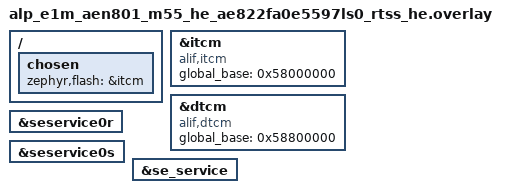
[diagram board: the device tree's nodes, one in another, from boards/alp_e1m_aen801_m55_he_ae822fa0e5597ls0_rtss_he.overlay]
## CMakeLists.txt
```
# SPDX-License-Identifier: Apache-2.0
#
# aen-se-crypto -- drive the portable <alp/security.h> compute surface
# (SHA-256 known-answer + AES-128-GCM round-trip + TRNG) on the E1M-AEN801
# (Ensemble E8, M55-HE) backed by the Secure Enclave's CryptoCell.  The
# companion to aen-se-service-query (which proves the READ-ONLY SE surface);
# this app exercises the *compute* services that ride the same MHUv2 -> SE
# mailbox, through the SE-CryptoCell security backend
# (src/backends/security/se_cryptocell.c).
#
# Plain prj.conf app (no alp_project.py board.yaml emit): the SE-service
# stack Kconfigs (CONFIG_ARM_MHUV2 / CONFIG_HAS_ALIF_SE_SERVICES) and the
# SE-CryptoCell backend gate (CONFIG_ALP_SDK_SECURITY_SE_CRYPTOCELL) are
# sourced under CONFIG_ALP_SDK, which prj.conf sets; the overlay okays the
# MHUv2 nodes + the se_service root node and supplies the itcm/dtcm
# global_base the SE address translation needs.

cmake_minimum_required(VERSION 3.20)

# No DTC_OVERLAY_FILE: Zephyr applies boards/<fully-qualified-board>.overlay
# by itself, so the AEN801 and AEN803 targets each read their own file.

find_package(Zephyr REQUIRED HINTS $ENV{ZEPHYR_BASE})
project(aen_se_crypto LANGUAGES C)

target_sources(app PRIVATE src/main.c)
```

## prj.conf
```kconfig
# SPDX-License-Identifier: Apache-2.0
#
# Bench RAM-run config for the E1M-AEN801 (M55-HE).

# Tier-2 driver Kconfigs (incl. CONFIG_ARM_MHUV2 / CONFIG_HAS_ALIF_SE_SERVICES
# and the alp-sdk security backends) are gated under ALP_SDK.
CONFIG_ALP_SDK=y

# SE service transport.  CONFIG_ARM_MHUV2 builds the in-tree "arm,mhuv2" IPM
# driver (zephyr/drivers/ipm/ipm_arm_mhuv2.c) and pulls in CONFIG_IPM;
# CONFIG_HAS_ALIF_SE_SERVICES compiles the hal_alif SE client
# (se_services/zephyr/src/se_service.c) the SE-CryptoCell backend rides.
CONFIG_ARM_MHUV2=y
CONFIG_HAS_ALIF_SE_SERVICES=y

# SE-CryptoCell hardware-crypto backend for <alp/security.h>.  Registers at
# silicon_ref="alif:ensemble:e8" priority 110 (ahead of the "*" PSA backend).
# RNG/TRNG runs live through the public se_service_get_rnd_num(); SHA/AES-GCM
# need the generic send seam below.
CONFIG_ALP_SDK_SECURITY_SE_CRYPTOCELL=y

# The generic SE send-request transport seam DEFAULTS ON (Kconfig default y):
# the public send-request entry now exists (hal_alif patch 0002 exposes
# se_service_send_request), so by default the SE backend's SHA/AES-GCM ops
# compute on-silicon in the SE CryptoCell (bench-validated, Flow C RAM-run) --
# the SE backend binds at priority 110 ahead of PSA.  No override is needed here.
# The MbedTLS-PSA backend below is only the fall-through for algs the SE declines
# (SHA-384/512, over-ceiling single-shot inputs).  To force a PSA-only
# fall-through demo instead, uncomment the next line:
# CONFIG_ALP_SDK_SECURITY_SE_CRYPTOCELL_SEND_SEAM is not set

# MbedTLS-PSA backend, kept as the fall-through for SE-declined algs (the SE
# send seam is ON by default, so SHA-256/AES-GCM run in the SE CryptoCell) --
# proves the portable API contract end to end.  PSA picks the E8 crypto HW
# where MbedTLS's driver layer registers it.
CONFIG_MBEDTLS=y
CONFIG_MBEDTLS_PSA_CRYPTO_C=y
CONFIG_ALP_SDK_SECURITY=y

# PSA wants for the example's ops: SHA-256 (works) + AES-GCM AEAD (the GCM
# round-trip reported "no backend" because PSA AEAD/GCM + AES key type were
# not selected, so the alp PSA backend declined the open).
CONFIG_PSA_WANT_ALG_SHA_256=y
CONFIG_PSA_WANT_ALG_GCM=y
CONFIG_PSA_WANT_KEY_TYPE_AES=y

# MbedTLS-PSA software AES-GCM/SHA is stack- and heap-heavy; the default main
# stack overflows (bench USAGE FAULT: stack overflow). Give the main thread
# room and a PSA heap pool.
CONFIG_MAIN_STACK_SIZE=16384
CONFIG_HEAP_MEM_POOL_SIZE=16384

# Console: Alp UART console -- E1M edge UART0 (Alif UART5, P3_4/P3_5, 115200
# 8N1, NS16550), the E1M-AEN801 carrier console. The board _defconfig already
# selects it; we set it explicitly here so the example is self-describing.
CONFIG_SERIAL=y
CONFIG_CONSOLE=y
CONFIG_UART_CONSOLE=y
CONFIG_UART_INTERRUPT_DRIVEN=y
# Serial-less bench? Comment the four lines above and uncomment these to read
# 'ram_console_buf' over SWD instead:
# CONFIG_RAM_CONSOLE=y
# CONFIG_RAM_CONSOLE_BUFFER_SIZE=2048
# CONFIG_UART_CONSOLE=n
CONFIG_PRINTK=y

# Keep the image small + deterministic for a RAM-run.
CONFIG_LOG=n
```

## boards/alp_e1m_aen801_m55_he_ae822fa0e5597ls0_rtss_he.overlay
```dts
/*
 * Copyright (c) 2026 Alp Lab AB
 * SPDX-License-Identifier: Apache-2.0
 *
 * aen-se-crypto overlay for the E1M-AEN801 (Ensemble E8, M55-HE) RAM-run.
 *
 * The SE SERVICE transport nodes live in the E8 SoC overlay
 * (zephyr/dts/alif/ensemble_e8_peripherals.dtsi) status="disabled" by
 * default (they are SoC-fixed: the RTSS-HE <-> SE MHUv2 mailbox pair + the
 * se_service root node).  This overlay enables them for the RTSS-HE core:
 *   - seservice0r (arm,mhuv2 @ 0x40040000, IRQ 37, "rx") -- SE -> RTSS in
 *   - seservice0s (arm,mhuv2 @ 0x40050000, IRQ 38, "tx") -- RTSS -> SE out
 *   - se_service  (alif,secure-enclave-services) -- ties the two via phandles
 *
 * Identical SE transport DT to aen-se-service-query; the SE-CryptoCell
 * security backend rides the very same se_service client.
 *
 * No clocks / pinctrl: the MHUv2 mailboxes are core-internal (no pads, no
 * peripheral clock gate); the driver only maps MMIO + wires the IRQ.
 */

/*
 * RAM-run: retarget ROM to ITCM (path-reference form &itcm; the
 * phandle-array form makes FLASH_SIZE=0 and overflows the link) -- the
 * aen-se-service-query precedent.
 */
/ {
	chosen {
		zephyr,flash = &itcm;
		/delete-property/ zephyr,code-partition;
	};
};

/*
 * itcm/dtcm `global_base` for local_to_global() -- the SE-CryptoCell
 * backend (and hal_alif se_service.c) put the outbound SE message buffer
 * through local_to_global() (soc_memory_map.h), which reads
 * DT_PROP(itcm/dtcm, global_base) to translate the M55-local address into
 * the global view the SE's DMA sees, AND the backend translates every
 * embedded send_*_addr the SE dereferences the same way.  Upstream Zephyr's
 * arm,itcm/arm,dtcm bindings have no such prop, so re-`compatible` the nodes
 * onto the alp-sdk alif,itcm/alif,dtcm bindings (which declare global_base)
 * and set the E8 RTSS-HE global TCM aliases (ITCM 0x58000000,
 * DTCM 0x58800000), transcribed from the Apache-2.0 zephyr_alif fork
 * ensemble_rtss_he.dtsi -- the same values the NPU + camera + eth + se-query
 * local_to_global paths use.
 */
&itcm {
	compatible = "alif,itcm";
	global_base = <0x58000000>;
};

&dtcm {
	compatible = "alif,dtcm";
	global_base = <0x58800000>;
};

&seservice0r {
	status = "okay";
};

&seservice0s {
	status = "okay";
};

&se_service {
	status = "okay";
};
```

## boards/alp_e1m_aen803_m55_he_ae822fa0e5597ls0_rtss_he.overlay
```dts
/*
 * Copyright (c) 2026 Alp Lab AB
 * SPDX-License-Identifier: Apache-2.0
 *
 * aen-se-crypto overlay for the E1M-AEN803 (Ensemble E8, M55-HE) RAM-run.
 *
 * The SE SERVICE transport nodes live in the E8 SoC overlay
 * (zephyr/dts/alif/ensemble_e8_peripherals.dtsi) status="disabled" by
 * default (they are SoC-fixed: the RTSS-HE <-> SE MHUv2 mailbox pair + the
 * se_service root node).  This overlay enables them for the RTSS-HE core:
 *   - seservice0r (arm,mhuv2 @ 0x40040000, IRQ 37, "rx") -- SE -> RTSS in
 *   - seservice0s (arm,mhuv2 @ 0x40050000, IRQ 38, "tx") -- RTSS -> SE out
 *   - se_service  (alif,secure-enclave-services) -- ties the two via phandles
 *
 * Identical SE transport DT to aen-se-service-query; the SE-CryptoCell
 * security backend rides the very same se_service client.
 *
 * No clocks / pinctrl: the MHUv2 mailboxes are core-internal (no pads, no
 * peripheral clock gate); the driver only maps MMIO + wires the IRQ.
 */

/*
 * RAM-run: retarget ROM to ITCM (path-reference form &itcm; the
 * phandle-array form makes FLASH_SIZE=0 and overflows the link) -- the
 * aen-se-service-query precedent.
 */
/ {
	chosen {
		zephyr,flash = &itcm;
		/delete-property/ zephyr,code-partition;
	};
};

/*
 * itcm/dtcm `global_base` for local_to_global() -- the SE-CryptoCell
 * backend (and hal_alif se_service.c) put the outbound SE message buffer
 * through local_to_global() (soc_memory_map.h), which reads
 * DT_PROP(itcm/dtcm, global_base) to translate the M55-local address into
 * the global view the SE's DMA sees, AND the backend translates every
 * embedded send_*_addr the SE dereferences the same way.  Upstream Zephyr's
 * arm,itcm/arm,dtcm bindings have no such prop, so re-`compatible` the nodes
 * onto the alp-sdk alif,itcm/alif,dtcm bindings (which declare global_base)
 * and set the E8 RTSS-HE global TCM aliases (ITCM 0x58000000,
 * DTCM 0x58800000), transcribed from the Apache-2.0 zephyr_alif fork
 * ensemble_rtss_he.dtsi -- the same values the NPU + camera + eth + se-query
 * local_to_global paths use.
 */
&itcm {
	compatible = "alif,itcm";
	global_base = <0x58000000>;
};

&dtcm {
	compatible = "alif,dtcm";
	global_base = <0x58800000>;
};

&seservice0r {
	status = "okay";
};

&seservice0s {
	status = "okay";
};

&se_service {
	status = "okay";
};
```

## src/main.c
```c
/*
 * Copyright (c) 2026 Alp Lab AB
 * SPDX-License-Identifier: Apache-2.0
 *
 * aen-se-crypto -- exercise the portable <alp/security.h> surface on the
 * E1M-AEN801 (Ensemble E8, M55-HE) when it is backed by the Secure
 * Enclave's CryptoCell HARDWARE crypto.
 *
 * This is the companion to aen-se-service-query: that app proves the
 * READ-ONLY SE transport binds and answers (heartbeat + LCS + 8-byte TRNG);
 * THIS app drives the *compute* surface that rides the same MHUv2 -> SE
 * mailbox -- a known-answer SHA-256, an AES-128-GCM encrypt/decrypt
 * round-trip, and a true-random pull -- all through the vendor-clean
 * alp_hash_* / alp_aead_* / alp_random_bytes API.  Nothing here names the
 * SE: the SE-CryptoCell backend (src/backends/security/se_cryptocell.c)
 * registers at silicon_ref="alif:ensemble:e8" priority 110 and wins
 * selection over the portable MbedTLS-PSA backend on this part, so the work
 * lands on dedicated silicon transparently.
 *
 * WHAT RUNS WHERE (current bench reality):
 *   - alp_random_bytes  -> SE TRNG, LIVE today (public
 *                          se_service_get_rnd_num under the hood).
 *   - alp_hash_* / alp_aead_*  -> SE CryptoCell SHA / AES-GCM.  These ride the
 *                          generic SE send-request seam
 *                          (CONFIG_ALP_SDK_SECURITY_SE_CRYPTOCELL_SEND_SEAM),
 *                          which DEFAULTS ON, so by default the SE CryptoCell
 *                          computes them on-silicon (bench-validated).  For an
 *                          alg the SE declines (SHA-384/512, over-ceiling
 *                          input) the dispatcher falls through to the
 *                          MbedTLS-PSA backend on the M55.  Either way the API
 *                          contract holds and the RESULT line reports which
 *                          surfaces answered.
 *
 * PASS gate: SHA-256("abc") matches the NIST known-answer vector, the
 * AES-128-GCM ciphertext decrypts back to the plaintext with a valid tag,
 * and the TRNG fill returns ALP_OK with not-all-zero bytes.
 *
 * Bench flow: RAM-run + RAM-console (the app UART is not on USB on this
 * bench; read 'ram_console_buf' over SWD).  Every alp_* call bounds its
 * wait inside the backend, so the app never hangs.
 */

#include <stdbool.h>
#include <stdint.h>
#include <string.h>

#include <zephyr/drivers/entropy.h>
#include <zephyr/kernel.h>
#include <zephyr/random/random.h>
#include <zephyr/sys/printk.h>

#include <alp/security.h>

/*
 * NIST FIPS 180-4 known-answer vector: SHA-256("abc").
 *   ba7816bf 8f01cfea 414140de 5dae2223
 *   b00361a3 96177a9c b410ff61 f20015ad
 */
static const uint8_t k_sha256_abc[32] = {
	0xba, 0x78, 0x16, 0xbf, 0x8f, 0x01, 0xcf, 0xea, 0x41, 0x41, 0x40, 0xde, 0x5d, 0xae, 0x22, 0x23,
	0xb0, 0x03, 0x61, 0xa3, 0x96, 0x17, 0x7a, 0x9c, 0xb4, 0x10, 0xff, 0x61, 0xf2, 0x00, 0x15, 0xad,
};

static void hexdump(const char *label, const uint8_t *p, size_t n)
{
	printk("        %s = ", label);
	for (size_t i = 0u; i < n; i++) {
		printk("%02x", p[i]);
	}
	printk("\n");
}

/* SHA-256("abc") through the portable hash surface. */
static bool test_sha256_abc(void)
{
	alp_hash_t *h = alp_hash_open(ALP_HASH_SHA256);
	if (h == NULL) {
		printk("sha256               : open FAILED (no backend)\n");
		return false;
	}

	uint8_t      digest[32] = { 0 };
	size_t       dlen       = 0u;
	alp_status_t s          = alp_hash_update(h, (const uint8_t *)"abc", 3u);
	if (s == ALP_OK) {
		s = alp_hash_finish(h, digest, sizeof(digest), &dlen);
		/* Contract nuance (<alp/security.h>): finish implicitly closes
		 * the context ON SUCCESS ONLY.  A failed finish leaves the
		 * handle open, so it must be closed explicitly or the backend
		 * slot leaks and later opens start failing. */
		if (s != ALP_OK) {
			alp_hash_close(h);
		}
	} else {
		/* Update failed before finish ever ran: release the handle
		 * (close is the "abandon without finalising" path). */
		alp_hash_close(h);
	}

	const bool ok = (s == ALP_OK) && (dlen == sizeof(digest)) &&
	                (memcmp(digest, k_sha256_abc, sizeof(digest)) == 0);
	printk("sha256(\"abc\")        : s=%d len=%zu %s\n", (int)s, dlen, ok ? "MATCH" : "MISMATCH");
	if (!ok) {
		hexdump("got        ", digest, sizeof(digest));
		hexdump("want       ", k_sha256_abc, sizeof(k_sha256_abc));
	}
	return ok;
}

/* AES-128-GCM encrypt then decrypt; the recovered plaintext must match. */
static bool test_aes128_gcm_roundtrip(void)
{
	/* Arbitrary but fixed key/IV so the run is deterministic. */
	const uint8_t key[16] = { 0x00, 0x01, 0x02, 0x03, 0x04, 0x05, 0x06, 0x07,
		                      0x08, 0x09, 0x0a, 0x0b, 0x0c, 0x0d, 0x0e, 0x0f };
	const uint8_t iv[12]  = {
		0x10, 0x11, 0x12, 0x13, 0x14, 0x15, 0x16, 0x17, 0x18, 0x19, 0x1a, 0x1b
	};
	const uint8_t aad[8]    = { 0xa0, 0xa1, 0xa2, 0xa3, 0xa4, 0xa5, 0xa6, 0xa7 };
	const uint8_t plain[19] = "alp-sdk SE crypto!";

	alp_aead_t *a = alp_aead_open(ALP_AEAD_AES_128_GCM, key, sizeof(key));
	if (a == NULL) {
		printk("aes128gcm            : open FAILED (no backend)\n");
		return false;
	}

	uint8_t      cipher[sizeof(plain)] = { 0 };
	uint8_t      tag[16]               = { 0 };
	alp_status_t se                    = alp_aead_encrypt(
	    a, iv, sizeof(iv), aad, sizeof(aad), plain, sizeof(plain), cipher, tag, sizeof(tag));
	if (se != ALP_OK) {
		printk("aes128gcm encrypt    : s=%d FAILED\n", (int)se);
		alp_aead_close(a);
		return false;
	}

	uint8_t      recovered[sizeof(plain)] = { 0 };
	alp_status_t sd                       = alp_aead_decrypt(
	    a, iv, sizeof(iv), aad, sizeof(aad), cipher, sizeof(cipher), tag, sizeof(tag), recovered);
	alp_aead_close(a);

	const bool ok = (sd == ALP_OK) && (memcmp(recovered, plain, sizeof(plain)) == 0);
	printk(
	    "aes128gcm round-trip : enc=%d dec=%d %s\n", (int)se, (int)sd, ok ? "MATCH" : "MISMATCH");
	if (ok) {
		hexdump("tag        ", tag, sizeof(tag));
	}
	return ok;
}

/* Pull 16 TRNG bytes; PASS requires ALP_OK and a not-all-zero result. */
static bool test_trng(void)
{
	uint8_t      rnd[16] = { 0 };
	alp_status_t s       = alp_random_bytes(rnd, sizeof(rnd));

	bool nonzero = false;
	for (size_t i = 0u; i < sizeof(rnd); i++) {
		if (rnd[i] != 0u) {
			nonzero = true;
			break;
		}
	}

	const bool ok = (s == ALP_OK) && nonzero;
	printk("trng(16)             : s=%d %s\n", (int)s, ok ? "OK" : "FAIL");
	if (s == ALP_OK) {
		hexdump("rnd        ", rnd, sizeof(rnd));
	}
	return ok;
}

/* The zephyr,entropy device (the SE TRNG, #2192) and the CSPRNG seeded from
 * it. 300 bytes crosses the SE's 256-byte single-request ceiling, so the
 * driver's chunking runs; two draws must differ and neither may be all-zero. */
static bool test_zephyr_entropy(void)
{
#if DT_HAS_CHOSEN(zephyr_entropy)
	const struct device *dev = DEVICE_DT_GET(DT_CHOSEN(zephyr_entropy));
	static uint8_t       a[300];
	static uint8_t       b[300];

	if (!device_is_ready(dev)) {
		printk("zephyr,entropy       : %s not ready FAIL\n", dev->name);
		return false;
	}
	int ra = entropy_get_entropy(dev, a, sizeof(a));
	int rb = entropy_get_entropy(dev, b, sizeof(b));

	bool nonzero = false;
	for (size_t i = 0u; i < sizeof(a); i++) {
		if ((a[i] != 0u) && (b[i] != 0u)) {
			nonzero = true;
			break;
		}
	}
	uint8_t cs[16] = { 0 };
	int     rc     = sys_csrand_get(cs, sizeof(cs));

	const bool differ = memcmp(a, b, sizeof(a)) != 0;
	const bool ok     = (ra == 0) && (rb == 0) && nonzero && differ && (rc == 0);
	printk("zephyr,entropy (%s): get=%d/%d differ=%d csrand=%d %s\n",
	       dev->name,
	       ra,
	       rb,
	       (int)differ,
	       rc,
	       ok ? "OK" : "FAIL");
	hexdump("entropy    ", a, 16);
	hexdump("csrand     ", cs, sizeof(cs));
	return ok;
#else
	printk("zephyr,entropy       : no chosen node in this build -- skipped\n");
	return true;
#endif
}

int main(void)
{
	printk("\n=== aen-se-crypto (SE CryptoCell via <alp/security.h>) ===\n");

	const bool sha_ok  = test_sha256_abc();
	const bool gcm_ok  = test_aes128_gcm_roundtrip();
	const bool trng_ok = test_trng();
	const bool ent_ok  = test_zephyr_entropy();

	if (sha_ok && gcm_ok && trng_ok && ent_ok) {
		printk("RESULT PASS: SHA-256(\"abc\") known-answer MATCH + AES-128-GCM round-trip "
		       "MATCH + TRNG OK + zephyr,entropy OK -- the portable <alp/security.h> surface "
		       "answered through the selected crypto backend (SE CryptoCell on E8 when the send "
		       "seam is "
		       "wired; MbedTLS-PSA fallthrough otherwise)\n");
	} else {
		printk("RESULT FAIL: sha=%d gcm=%d trng=%d entropy=%d -- see the per-test lines above (a "
		       "MISMATCH means the backend computed a wrong value; a 'no backend' open "
		       "FAIL means no security backend linked / selected)\n",
		       (int)sha_ok,
		       (int)gcm_ok,
		       (int)trng_ok,
		       (int)ent_ok);
	}

	return 0;
}
```
